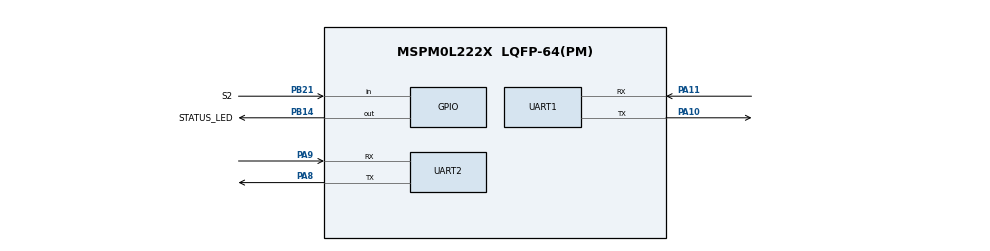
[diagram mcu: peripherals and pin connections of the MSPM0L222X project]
/**
 * @cliArgs --device "MSPM0L222X" --part "Default" --package "LQFP-64(PM)" --product "mspm0_sdk@2.06.00.05"
 * @versions {"tool":"1.26.2+4477"}
 */

/**
 * Import the modules used in this configuration.
 */
const Board         = scripting.addModule("/ti/driverlib/Board");
const GPIO          = scripting.addModule("/ti/driverlib/GPIO", {}, false);
const GPIO1         = GPIO.addInstance();
const GPIO2         = GPIO.addInstance();
const UART          = scripting.addModule("/ti/driverlib/UART", {}, false);
const UART1         = UART.addInstance();
const UART2         = UART.addInstance();
const ProjectConfig = scripting.addModule("/ti/project_config/ProjectConfig");

/**
 * Write custom configuration values to the imported modules.
 */

GPIO1.$name                          = "LEDS";
GPIO1.port                           = "PORTB";
GPIO1.associatedPins[0].$name        = "STATUS_LED";
GPIO1.associatedPins[0].initialValue = "SET";
GPIO1.associatedPins[0].pin.$assign  = "PB14";

GPIO2.$name                              = "BUTTONS";
GPIO2.port                               = "PORTB";
GPIO2.associatedPins[0].direction        = "INPUT";
GPIO2.associatedPins[0].internalResistor = "PULL_UP";
GPIO2.associatedPins[0].$name            = "S2";
GPIO2.associatedPins[0].pin.$assign      = "PB21";

const SYSCTL = scripting.addModule("/ti/driverlib/SYSCTL", {}, false);

UART1.$name                    = "UART_0";
UART1.targetBaudRate           = 115200;
UART1.rxFifoThreshold          = "DL_UART_RX_FIFO_LEVEL_ONE_ENTRY";
UART1.enableDMARX              = false;
UART1.enableDMATX              = false;
UART1.enableInternalLoopback   = false;
UART1.enableFIFO               = false;
UART1.peripheral.$assign       = "UART0";
UART1.peripheral.rxPin.$assign = "PA11";
UART1.peripheral.txPin.$assign = "PA10";
UART1.txPinConfig.$name        = "ti_driverlib_gpio_GPIOPinGeneric0";
UART1.rxPinConfig.$name        = "ti_driverlib_gpio_GPIOPinGeneric1";

UART2.$name                    = "UART_1";
UART2.targetBaudRate           = 115200;
UART2.peripheral.$assign       = "UART1";
UART2.peripheral.rxPin.$assign = "PA9";
UART2.peripheral.txPin.$assign = "PA8";
UART2.txPinConfig.$name        = "ti_driverlib_gpio_GPIOPinGeneric2";
UART2.rxPinConfig.$name        = "ti_driverlib_gpio_GPIOPinGeneric3";

ProjectConfig.compiler = "ticlang";

/**
 * Pinmux solution for unlocked pins/peripherals. This ensures that minor changes to the automatic solver in a future
 * version of the tool will not impact the pinmux you originally saw.  These lines can be completely deleted in order to
 * re-solve from scratch.
 */
Board.peripheral.$suggestSolution          = "DEBUGSS";
Board.peripheral.swclkPin.$suggestSolution = "PA20";
Board.peripheral.swdioPin.$suggestSolution = "PA19";
SYSCTL.peripheral.$suggestSolution         = "SYSCTL";
